AUTOSAR XML (schema 00047)
package /Components
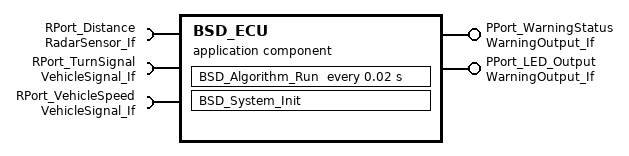
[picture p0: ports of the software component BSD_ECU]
  application sw component type BSD_ECU
    require port RPort_Distance: nonqueued-receiver-com-spec{data-element=Distance, init-value=0}, required-interface=RadarSensor_If
    require port RPort_TurnSignal: nonqueued-receiver-com-spec{data-element=TurnSignal__, init-value=0}, required-interface=VehicleSignal_If
    require port RPort_VehicleSpeed: nonqueued-receiver-com-spec{data-element=VehicleSpeed, init-value=0}, required-interface=VehicleSignal_If
    provide port PPort_WarningStatus: nonqueued-sender-com-spec{data-element=WarningStatus, init-value=0}, provided-interface=WarningOutput_If
    provide port PPort_LED_Output: nonqueued-sender-com-spec{data-element=LED_Output, init-value=0}, provided-interface=WarningOutput_If
    behavior BSD_System_IB: handle-termination-and-restart=NO-SUPPORT
      timing event Time_20ms: start-on-event=BSD_Algorithm_Run, period=0.02
      runnable BSD_System_Init
      runnable BSD_Algorithm_Run
        data-read-access:
          access IN_RPort_Distance_Distance: accessed-variable=RPort_Distance.Distance
          access IN_RPort_TurnSignal_TurnSignal: accessed-variable=RPort_TurnSignal.TurnSignal__
          access IN_RPort_VehicleSpeed_VehicleSpeed: accessed-variable=RPort_VehicleSpeed.VehicleSpeed
        data-write-access:
          access OUT_PPort_WarningStatus_WarningStatus: accessed-variable=PPort_WarningStatus.WarningStatus
          access OUT_PPort_LED_Output_LED_Output: accessed-variable=PPort_LED_Output.LED_Output
